# ATmega169PA device description
Architecture: AVR8; Family: megaAVR
Registers are 8-bit, access not given, no defined reset value unless marked. A register's access mark holds for its fields unless they carry their own. Offsets are from the block's base; [hi:lo] are bit positions; {n}, {i} and the like mark numbered series.

## PORTF — I/O Port
Instances: PORTF 0x00
0x2F PINF — Input Pins, Port F
0x30 DDRF — Data Direction Register, Port F
0x31 PORTF — Data Register, Port F

## PORTG — I/O Port
Instances: PORTG 0x00
0x32 PING bits used 5:0 — Port G Input Pins
0x33 DDRG bits used 5:0 — Port G Data Direction Register
0x34 PORTG bits used 5:0 — Port G Data Register

## AC — Analog Comparator
Instances: AC 0x00
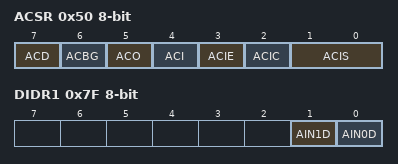
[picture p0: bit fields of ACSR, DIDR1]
0x50 ACSR — Analog Comparator Control And Status Register
  [7] ACD — Analog Comparator Disable
  [6] ACBG — Analog Comparator Bandgap Select
  [5] ACO — Analog Compare Output
  [4] ACI — Analog Comparator Interrupt Flag
  [3] ACIE — Analog Comparator Interrupt Enable
  [2] ACIC — Analog Comparator Input Capture Enable
  [1:0] ACIS — Analog Comparator Interrupt Mode Select bits
    0=Interrupt on Toggle; 2=Interrupt on Falling Edge; 3=Interrupt on Rising Edge
0x7B ADCSRB — ADC Control and Status Register B
  [6] ACME — Analog Comparator Multiplexer Enable
0x7F DIDR1 — Digital Input Disable Register 1
  [1] AIN1D — AIN1 Digital Input Disable
  [0] AIN0D — AIN0 Digital Input Disable

## JTAG — JTAG Interface
Instances: JTAG 0x00
0x51 OCDR — On-Chip Debug Related Register in I/O Memory
0x54 MCUSR — MCU Status Register
  [4] JTRF — JTAG Reset Flag
0x55 MCUCR — MCU Control Register
  [7] JTD — JTAG Interface Disable

## LCD — Liquid Crystal Display
Instances: LCD 0x00
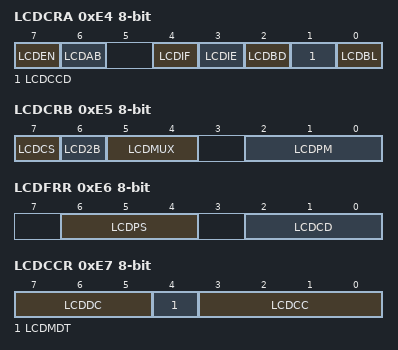
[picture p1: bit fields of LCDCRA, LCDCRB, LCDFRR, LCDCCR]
0xE4 LCDCRA — LCD Control Register A
  [7] LCDEN — LCD Enable
  [6] LCDAB — LCD A or B waveform
  [4] LCDIF — LCD Interrupt Flag
  [3] LCDIE — LCD Interrupt Enable
  [2] LCDBD — LCD Buffer Disable
  [1] LCDCCD — LCD Contrast Control Disable
  [0] LCDBL — LCD Blanking
0xE5 LCDCRB — LCD Control and Status Register B
  [7] LCDCS — LCD CLock Select
  [6] LCD2B — LCD 1/2 Bias Select
  [5:4] LCDMUX — LCD Mux Selects
  [2:0] LCDPM — LCD Port Masks
    0=SEG0:12; 1=SEG0:14; 2=SEG0:15; 3=SEG0:18; 4=SEG0:20; 5=SEG0:22; 6=SEG0:23; 7=SEG0:24
0xE6 LCDFRR — LCD Frame Rate Register
  [6:4] LCDPS — LCD Prescaler Selects
    0=ClkLCD/16; 1=ClkLCD/64; 2=ClkLCD/128; 3=ClkLCD/256; 4=ClkLCD/512; 5=ClkLCD/1024; 6=ClkLCD/2048; 7=ClkLCD/4096
  [2:0] LCDCD — LCD Clock Dividers
    {v}={v+1} (v=0..7)
0xE7 LCDCCR — LCD Contrast Control Register
  [7:5] LCDDC — LCD Display Configuration Bits
    0=300us; 1=70us; 2=150us; 3=450us; 4=575us; 5=850us; 6=1150us; 7=50% of LCD clock
  [4] LCDMDT — LCD Maximum Drive Time
  [3:0] LCDCC — LCD Contrast Controls
    0=2.60V; 1=2.65V; 2=2.70V; 3=2.75V; 4=2.80V; 5=2.85V; 6=2.90V; 7=2.95V; 8=3.00V; 9=3.05V; 10=3.10V; 11=3.15V; 12=3.20V; 13=3.25V; 14=3.30V; 15=3.35V
{0xEC+i} LCDDR{i} (i=0..2) — LCD Data Register {i}
0xEF LCDDR3 bits used 0 — LCD Data Register 3
{0xEC+i} LCDDR{i} (i=5..7) — LCD Data Register {i}
0xF4 LCDDR8 bits used 0 — LCD Data Register 8
{0xEC+i} LCDDR{i} (i=10..12) — LCD Data Register {i}
0xF9 LCDDR13 bits used 0 — LCD Data Register 13
{0xEC+i} LCDDR{i} (i=15..17) — LCD Data Register {i}
0xFE LCDDR18 bits used 0 — LCD Data Register 18

## USI — Universal Serial Interface
Instances: USI 0x00
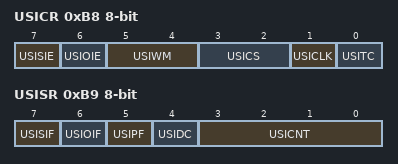
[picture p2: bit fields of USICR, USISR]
0xB8 USICR — USI Control Register
  [7] USISIE — Start Condition Interrupt Enable
  [6] USIOIE — Counter Overflow Interrupt Enable
  [5:4] USIWM — USI Wire Mode Bits
    0=Normal Operation; 1=Three-Wire Mode; 2=Two-Wire Mode; 3=Two-Wire Mode Held Low
  [3:2] USICS — USI Clock Source Select Bits
  [1] USICLK — Clock Strobe
  [0] USITC — Toggle Clock Port Pin
0xB9 USISR — USI Status Register
  [7] USISIF — Start Condition Interrupt Flag
  [6] USIOIF — Counter Overflow Interrupt Flag
  [5] USIPF — Stop Condition Flag
  [4] USIDC — Data Output Collision
  [3:0] USICNT — USI Counter Value Bits
0xBA USIDR — USI Data Register
  [7:0] USIDR — USI Data bits
